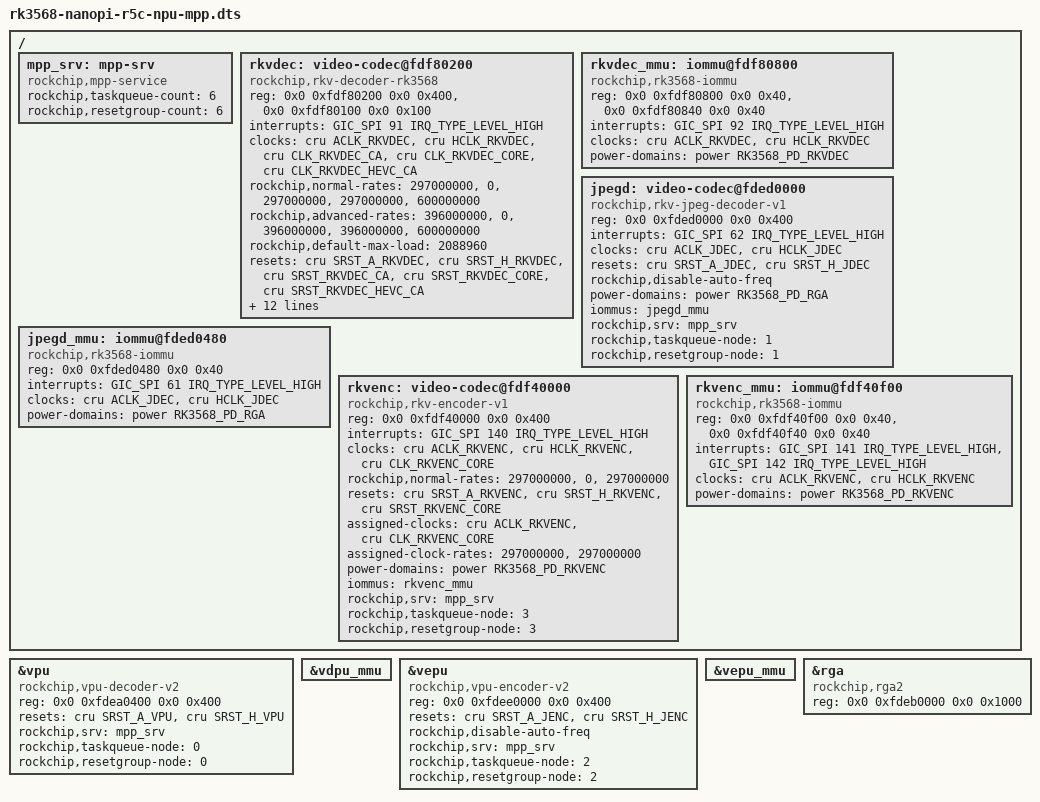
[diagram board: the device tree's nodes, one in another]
// SPDX-License-Identifier: GPL-2.0-or-later OR MIT
/* RK3568 SDK MPP codecs with the existing NPU SCMI/OPP configuration. */
#include "rk3568-nanopi-r5c-npu-scmi-opp.dts"


&vpu {
	compatible = "rockchip,vpu-decoder-v2";
	reg = <0x0 0xfdea0400 0x0 0x400>;
	clock-names = "aclk_vcodec", "hclk_vcodec";
	resets = <&cru SRST_A_VPU>, <&cru SRST_H_VPU>;
	reset-names = "video_a", "video_h";
	rockchip,srv = <&mpp_srv>;
	rockchip,taskqueue-node = <0>;
	rockchip,resetgroup-node = <0>;
	status = "okay";
};

&vdpu_mmu { status = "okay"; };

&vepu {
	compatible = "rockchip,vpu-encoder-v2";
	reg = <0x0 0xfdee0000 0x0 0x400>;
	clock-names = "aclk_vcodec", "hclk_vcodec";
	resets = <&cru SRST_A_JENC>, <&cru SRST_H_JENC>;
	reset-names = "video_a", "video_h";
	rockchip,disable-auto-freq;
	rockchip,srv = <&mpp_srv>;
	rockchip,taskqueue-node = <2>;
	rockchip,resetgroup-node = <2>;
	status = "okay";
};

&vepu_mmu { status = "okay"; };

/ {
	mpp_srv: mpp-srv {
		compatible = "rockchip,mpp-service";
		rockchip,taskqueue-count = <6>;
		rockchip,resetgroup-count = <6>;
	};

	rkvdec: video-codec@fdf80200 {
		compatible = "rockchip,rkv-decoder-rk3568";
		reg = <0x0 0xfdf80200 0x0 0x400>,
		      <0x0 0xfdf80100 0x0 0x100>;
		reg-names = "regs", "link";
		interrupts = <GIC_SPI 91 IRQ_TYPE_LEVEL_HIGH>;
		interrupt-names = "irq_dec";
		clocks = <&cru ACLK_RKVDEC>, <&cru HCLK_RKVDEC>,
			 <&cru CLK_RKVDEC_CA>, <&cru CLK_RKVDEC_CORE>,
			 <&cru CLK_RKVDEC_HEVC_CA>;
		clock-names = "aclk_vcodec", "hclk_vcodec", "clk_cabac",
			      "clk_core", "clk_hevc_cabac";
		rockchip,normal-rates = <297000000>, <0>, <297000000>,
					<297000000>, <600000000>;
		rockchip,advanced-rates = <396000000>, <0>, <396000000>,
					  <396000000>, <600000000>;
		rockchip,default-max-load = <2088960>;
		resets = <&cru SRST_A_RKVDEC>, <&cru SRST_H_RKVDEC>,
			 <&cru SRST_RKVDEC_CA>, <&cru SRST_RKVDEC_CORE>,
			 <&cru SRST_RKVDEC_HEVC_CA>;
		reset-names = "video_a", "video_h", "video_cabac",
			      "video_core", "video_hevc_cabac";
		assigned-clocks = <&cru ACLK_RKVDEC>, <&cru CLK_RKVDEC_CA>,
				  <&cru CLK_RKVDEC_CORE>, <&cru CLK_RKVDEC_HEVC_CA>;
		assigned-clock-rates = <297000000>, <297000000>,
				       <297000000>, <297000000>;
		power-domains = <&power RK3568_PD_RKVDEC>;
		iommus = <&rkvdec_mmu>;
		rockchip,srv = <&mpp_srv>;
		rockchip,taskqueue-node = <4>;
		rockchip,resetgroup-node = <4>;
		rockchip,task-capacity = <16>;
		/* Use the SDK direct path while link/H.264 recovery is audited. */
		rockchip,disable-link-mode;
		/* Fixed RCB IOVA reservation is deferred until basic decode works. */
	};

	rkvdec_mmu: iommu@fdf80800 {
		compatible = "rockchip,rk3568-iommu";
		reg = <0x0 0xfdf80800 0x0 0x40>,
		      <0x0 0xfdf80840 0x0 0x40>;
		interrupts = <GIC_SPI 92 IRQ_TYPE_LEVEL_HIGH>;
		clocks = <&cru ACLK_RKVDEC>, <&cru HCLK_RKVDEC>;
		clock-names = "aclk", "iface";
		power-domains = <&power RK3568_PD_RKVDEC>;
		#iommu-cells = <0>;
	};

	jpegd: video-codec@fded0000 {
		compatible = "rockchip,rkv-jpeg-decoder-v1";
		reg = <0x0 0xfded0000 0x0 0x400>;
		interrupts = <GIC_SPI 62 IRQ_TYPE_LEVEL_HIGH>;
		clocks = <&cru ACLK_JDEC>, <&cru HCLK_JDEC>;
		clock-names = "aclk_vcodec", "hclk_vcodec";
		resets = <&cru SRST_A_JDEC>, <&cru SRST_H_JDEC>;
		reset-names = "video_a", "video_h";
		rockchip,disable-auto-freq;
		power-domains = <&power RK3568_PD_RGA>;
		iommus = <&jpegd_mmu>;
		rockchip,srv = <&mpp_srv>;
		rockchip,taskqueue-node = <1>;
		rockchip,resetgroup-node = <1>;
	};

	jpegd_mmu: iommu@fded0480 {
		compatible = "rockchip,rk3568-iommu";
		reg = <0x0 0xfded0480 0x0 0x40>;
		interrupts = <GIC_SPI 61 IRQ_TYPE_LEVEL_HIGH>;
		clocks = <&cru ACLK_JDEC>, <&cru HCLK_JDEC>;
		clock-names = "aclk", "iface";
		power-domains = <&power RK3568_PD_RGA>;
		#iommu-cells = <0>;
	};

	rkvenc: video-codec@fdf40000 {
		compatible = "rockchip,rkv-encoder-v1";
		reg = <0x0 0xfdf40000 0x0 0x400>;
		interrupts = <GIC_SPI 140 IRQ_TYPE_LEVEL_HIGH>;
		interrupt-names = "irq_enc";
		clocks = <&cru ACLK_RKVENC>, <&cru HCLK_RKVENC>, <&cru CLK_RKVENC_CORE>;
		clock-names = "aclk_vcodec", "hclk_vcodec", "clk_core";
		rockchip,normal-rates = <297000000>, <0>, <297000000>;
		resets = <&cru SRST_A_RKVENC>, <&cru SRST_H_RKVENC>, <&cru SRST_RKVENC_CORE>;
		reset-names = "video_a", "video_h", "video_core";
		assigned-clocks = <&cru ACLK_RKVENC>, <&cru CLK_RKVENC_CORE>;
		assigned-clock-rates = <297000000>, <297000000>;
		power-domains = <&power RK3568_PD_RKVENC>;
		iommus = <&rkvenc_mmu>;
		rockchip,srv = <&mpp_srv>;
		rockchip,taskqueue-node = <3>;
		rockchip,resetgroup-node = <3>;
	};

	rkvenc_mmu: iommu@fdf40f00 {
		compatible = "rockchip,rk3568-iommu";
		reg = <0x0 0xfdf40f00 0x0 0x40>, <0x0 0xfdf40f40 0x0 0x40>;
		interrupts = <GIC_SPI 141 IRQ_TYPE_LEVEL_HIGH>, <GIC_SPI 142 IRQ_TYPE_LEVEL_HIGH>;
		clocks = <&cru ACLK_RKVENC>, <&cru HCLK_RKVENC>;
		clock-names = "aclk", "iface";
		power-domains = <&power RK3568_PD_RKVENC>;
		#iommu-cells = <0>;
	};

};


&rga {
	compatible = "rockchip,rga2";
	reg = <0x0 0xfdeb0000 0x0 0x1000>;
	clock-names = "aclk_rga", "hclk_rga", "clk_rga";
	status = "okay";
};
